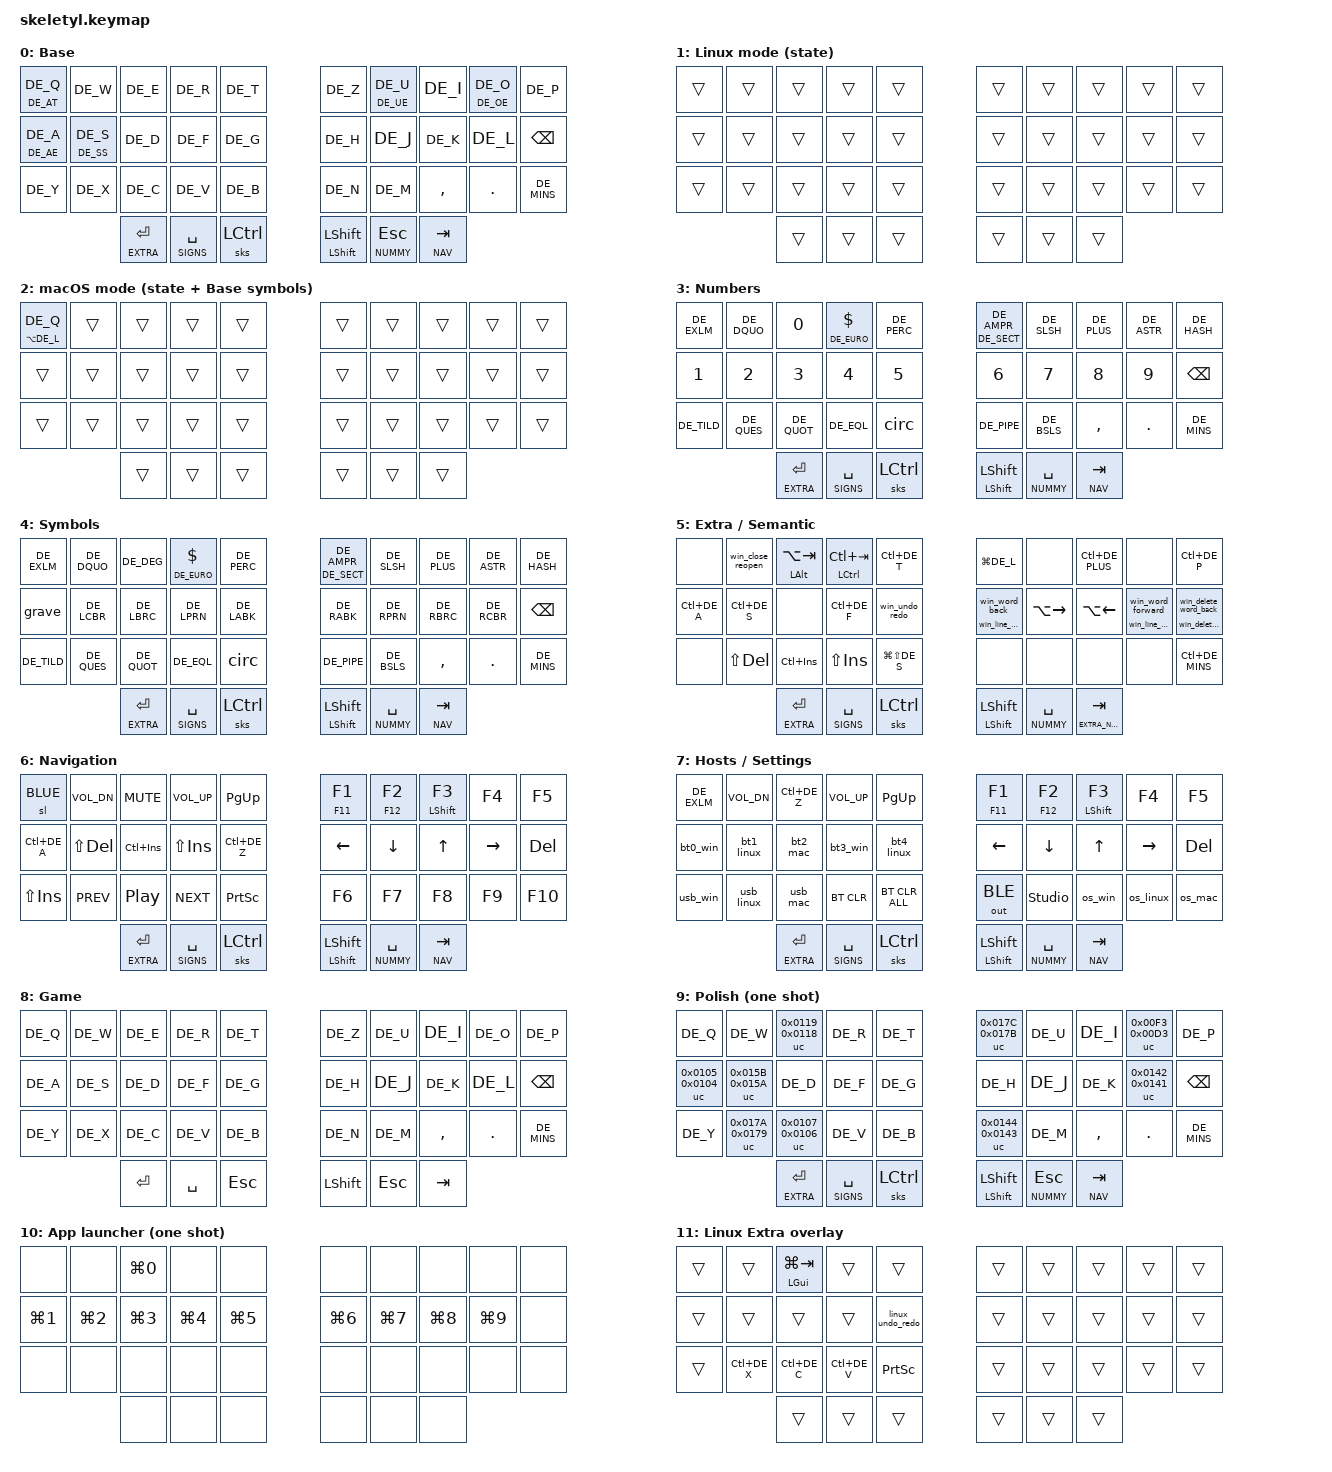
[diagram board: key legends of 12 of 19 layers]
#include "german-keymap.h"
#include <behaviors.dtsi>
#include <behaviors/unicode.dtsi>
#include <dt-bindings/zmk/keys.h>
#include <dt-bindings/zmk/bt.h>
#include <dt-bindings/zmk/outputs.h>
#include <dt-bindings/zmk/modifiers.h>

// Hardware-specific settings action. Boards with RGB can override this before
// including this keymap; the Skeletyl keeps its existing BLUE+Q exclamation.
#ifndef SETTINGS_PRIMARY
#define SETTINGS_PRIMARY &kp DE_EXLM
#endif

#define DEFAULT       0
// OS state layers deliberately sit below every functional layer. This lets
// macOS override Base symbols without leaking those overrides into NUMMY, etc.
#define LINUX_MODE    1
#define MAC_MODE      2
#define NUMMY         3
#define SIGNS         4
#define EXTRA         5
#define NAV           6
#define BLUE          7
#define GAME          8
#define POLISH        9
#define APP          10
#define LINUX_EXTRA  11
#define LINUX_NAV    12
#define MAC_EXTRA    13
#define MAC_NAV      14
#define MAC_NUMMY    15
#define MAC_SIGNS    16
#define EXTRA_NUM    17
#define MAC_EXTRA_NUM 18

#define STICKY_TIMEOUT_MS 500

&mt {
    flavor = "tap-preferred";
    tapping-term-ms = <180>;
};

&lt {
    tapping-term-ms = <160>;
};


// Unicode input. OS selectors below keep this mode in sync with the host.
&uc {
    default-mode = <UC_MODE_LINUX>;
};

/ {
    behaviors {
        sks: sticky_modifier {
            compatible = "zmk,behavior-sticky-key";
            #binding-cells = <1>;
            display-name = "Sticky modifier (500 ms)";
            bindings = <&kp>;
            release-after-ms = <STICKY_TIMEOUT_MS>;
            // Deliberately no quick-release: this keeps the sticky modifier active
            // through the full next key press/release and avoids known interactions
            // with hold-tap based switcher keys.
            ignore-modifiers;
        };


        // Polish one-shot layer that survives modifier presses. Unlike ZMK's
        // standard &sl (quick-release), this stays active through Shift and
        // releases only after the actual non-modifier Polish key is released.
        pls: polish_sticky_layer {
            compatible = "zmk,behavior-sticky-key";
            #binding-cells = <1>;
            display-name = "Polish one-shot (modifier aware)";
            bindings = <&mo>;
            release-after-ms = <2000>;
            ignore-modifiers;
        };

        // Unicode needs Shift to remain active while &uc evaluates the key.
        // No quick-release here: tap Shift, then the Polish letter.
        pl_sks: polish_sticky_shift {
            compatible = "zmk,behavior-sticky-key";
            #binding-cells = <1>;
            display-name = "Polish sticky Shift";
            bindings = <&kp>;
            release-after-ms = <1500>;
            ignore-modifiers;
        };

        // Right Shift thumb: quick tap keeps the existing sticky-Shift UX;
        // holding it behaves like a normal physical Shift. This is essential
        // for repeatedly walking backwards through an open switcher.
        shft: shift_hold_sticky_tap {
            compatible = "zmk,behavior-hold-tap";
            #binding-cells = <2>;
            display-name = "Shift hold / sticky tap";
            flavor = "hold-preferred";
            tapping-term-ms = <180>;
            quick-tap-ms = <0>;
            bindings = <&kp>, <&sks>;
        };

        // Same dual Shift on the Polish layer, but the tap uses the
        // non-quick-release sticky Shift so Unicode reliably sees Shift.
        pl_shft: polish_shift_hold_sticky_tap {
            compatible = "zmk,behavior-hold-tap";
            #binding-cells = <2>;
            display-name = "Polish Shift hold / sticky tap";
            flavor = "hold-preferred";
            tapping-term-ms = <180>;
            quick-tap-ms = <0>;
            bindings = <&kp>, <&pl_sks>;
        };

        tog_on: toggle_layer_on_only {
            compatible = "zmk,behavior-toggle-layer";
            #binding-cells = <1>;
            display-name = "Layer ON";
            toggle-mode = "on";
        };

        tog_off: toggle_layer_off_only {
            compatible = "zmk,behavior-toggle-layer";
            #binding-cells = <1>;
            display-name = "Layer OFF";
            toggle-mode = "off";
        };

        hm: function_shift {
            compatible = "zmk,behavior-hold-tap";
            #binding-cells = <2>;
            display-name = "Function / Shift";
            tapping-term-ms = <150>;
            quick-tap-ms = <0>;
            flavor = "tap-preferred";
            bindings = <&kp>, <&kp>;
        };

        pht: positional_hold_tap {
            compatible = "zmk,behavior-hold-tap";
            #binding-cells = <2>;
            display-name = "Positional hold-tap";
            flavor = "hold-preferred";
            tapping-term-ms = <180>;
            quick-tap-ms = <180>;
            bindings = <&kp>, <&kp>;
            hold-trigger-key-positions = <29>;
        };

        // Robust switcher key: tap sends a complete one-step shortcut; hold sends
        // only the underlying modifier. There are no macros, toggles, or cross-key
        // cleanup states, so releasing the physical E/R key always releases the
        // modifier via normal &kp semantics.
        //
        // Usage examples:
        //   &swh LALT  LA(TAB)  -> tap: Alt+Tab, hold: Alt (Windows)
        //   &swh LGUI  LG(TAB)  -> tap: Super/Cmd+Tab, hold: Super/Cmd (Linux/macOS)
        //   &swh LCTRL LC(TAB)  -> tap: Ctrl+Tab, hold: Ctrl
        swh: switcher_hold_tap {
            compatible = "zmk,behavior-hold-tap";
            #binding-cells = <2>;
            display-name = "Switcher tap / hold modifier";
            flavor = "hold-preferred";
            tapping-term-ms = <180>;
            quick-tap-ms = <0>;
            // The hold modifier is asserted immediately. Because the tap action
            // contains that same modifier (Alt/Super/Ctrl + Tab), linger keeps the
            // modifier continuous across the tap decision instead of releasing and
            // pressing it again.
            hold-while-undecided;
            hold-while-undecided-linger;
            bindings = <&kp>, <&kp>;
        };

        // EXTRA right outer thumb: tapping remains Tab for app/tab switchers,
        // while pressing immediately exposes the forward-delete overlay so a
        // following Backspace is handled as Delete. Holding selects the layer.
        fwd: forward_delete_tab {
            compatible = "zmk,behavior-hold-tap";
            #binding-cells = <2>;
            display-name = "Forward delete layer / Tab";
            flavor = "tap-preferred";
            tapping-term-ms = <180>;
            quick-tap-ms = <0>;
            hold-while-undecided;
            bindings = <&mo>, <&kp>;
        };


        // Semantic shortcuts with Shift-aware alternate actions. App/tab switching uses
        // only the hold-tap above and normal &kp events; there is no latched modifier
        // state to clean up.
        win_close_reopen: win_close_reopen {
            compatible = "zmk,behavior-mod-morph";
            #binding-cells = <0>;
            display-name = "Close / Reopen tab";
            bindings = <&kp LC(DE_W)>, <&kp LC(LS(DE_T))>;
            mods = <(MOD_LSFT|MOD_RSFT)>;
        };

        mac_close_reopen: mac_close_reopen {
            compatible = "zmk,behavior-mod-morph";
            #binding-cells = <0>;
            display-name = "Close / Reopen tab (macOS)";
            bindings = <&kp LG(DE_W)>, <&kp LG(LS(DE_T))>;
            mods = <(MOD_LSFT|MOD_RSFT)>;
        };


        win_undo_redo: win_undo_redo {
            compatible = "zmk,behavior-mod-morph";
            #binding-cells = <0>;
            display-name = "Undo / Redo (Windows)";
            bindings = <&kp LC(DE_Z)>, <&kp LC(DE_Y)>;
            mods = <(MOD_LSFT|MOD_RSFT)>;
        };

        linux_undo_redo: linux_undo_redo {
            compatible = "zmk,behavior-mod-morph";
            #binding-cells = <0>;
            display-name = "Undo / Redo (Linux)";
            bindings = <&kp LC(DE_Z)>, <&kp LC(LS(DE_Z))>;
            mods = <(MOD_LSFT|MOD_RSFT)>;
        };

        mac_undo_redo: mac_undo_redo {
            compatible = "zmk,behavior-mod-morph";
            #binding-cells = <0>;
            display-name = "Undo / Redo (macOS)";
            bindings = <&kp LG(DE_Z)>, <&kp LG(LS(DE_Z))>;
            mods = <(MOD_LSFT|MOD_RSFT)>;
        };

        // EXTRA is semantic: the same physical key performs the same editing
        // operation on every OS. Shift extends the operation to selection or
        // deletion up to the corresponding line boundary.
        win_word_back: win_word_back {
            compatible = "zmk,behavior-mod-morph";
            #binding-cells = <0>;
            display-name = "Word back / select word back";
            bindings = <&kp LC(LEFT)>, <&kp LC(LS(LEFT))>;
            mods = <(MOD_LSFT|MOD_RSFT)>;
        };

        win_word_forward: win_word_forward {
            compatible = "zmk,behavior-mod-morph";
            #binding-cells = <0>;
            display-name = "Word forward / select word forward";
            bindings = <&kp LC(RIGHT)>, <&kp LC(LS(RIGHT))>;
            mods = <(MOD_LSFT|MOD_RSFT)>;
        };

        win_line_start: win_line_start {
            compatible = "zmk,behavior-mod-morph";
            #binding-cells = <0>;
            display-name = "Line start / select to line start";
            bindings = <&kp HOME>, <&kp LS(HOME)>;
            mods = <(MOD_LSFT|MOD_RSFT)>;
        };

        win_line_end: win_line_end {
            compatible = "zmk,behavior-mod-morph";
            #binding-cells = <0>;
            display-name = "Line end / select to line end";
            bindings = <&kp END>, <&kp LS(END)>;
            mods = <(MOD_LSFT|MOD_RSFT)>;
        };

        mac_word_back: mac_word_back {
            compatible = "zmk,behavior-mod-morph";
            #binding-cells = <0>;
            display-name = "Word back / select word back (macOS)";
            bindings = <&kp LA(LEFT)>, <&kp LA(LS(LEFT))>;
            mods = <(MOD_LSFT|MOD_RSFT)>;
        };

        mac_word_forward: mac_word_forward {
            compatible = "zmk,behavior-mod-morph";
            #binding-cells = <0>;
            display-name = "Word forward / select word forward (macOS)";
            bindings = <&kp LA(RIGHT)>, <&kp LA(LS(RIGHT))>;
            mods = <(MOD_LSFT|MOD_RSFT)>;
        };

        mac_line_start: mac_line_start {
            compatible = "zmk,behavior-mod-morph";
            #binding-cells = <0>;
            display-name = "Line start / select to line start (macOS)";
            bindings = <&kp LG(LEFT)>, <&kp LG(LS(LEFT))>;
            mods = <(MOD_LSFT|MOD_RSFT)>;
        };

        mac_line_end: mac_line_end {
            compatible = "zmk,behavior-mod-morph";
            #binding-cells = <0>;
            display-name = "Line end / select to line end (macOS)";
            bindings = <&kp LG(RIGHT)>, <&kp LG(LS(RIGHT))>;
            mods = <(MOD_LSFT|MOD_RSFT)>;
        };

        // Short H/L moves by word; holding the same key moves to the matching
        // line boundary. The nested mod-morphs above preserve Shift selection.
        // ZMK hold-taps always expose two binding cells; these fixed-action
        // instances are therefore invoked with two ignored zero parameters.
        win_semantic_h: win_semantic_h {
            compatible = "zmk,behavior-hold-tap";
            #binding-cells = <2>;
            display-name = "Word back / line start";
            flavor = "tap-preferred";
            tapping-term-ms = <180>;
            quick-tap-ms = <0>;
            bindings = <&win_line_start>, <&win_word_back>;
        };

        win_semantic_l: win_semantic_l {
            compatible = "zmk,behavior-hold-tap";
            #binding-cells = <2>;
            display-name = "Word forward / line end";
            flavor = "tap-preferred";
            tapping-term-ms = <180>;
            quick-tap-ms = <0>;
            bindings = <&win_line_end>, <&win_word_forward>;
        };

        mac_semantic_h: mac_semantic_h {
            compatible = "zmk,behavior-hold-tap";
            #binding-cells = <2>;
            display-name = "Word back / line start (macOS)";
            flavor = "tap-preferred";
            tapping-term-ms = <180>;
            quick-tap-ms = <0>;
            bindings = <&mac_line_start>, <&mac_word_back>;
        };

        mac_semantic_l: mac_semantic_l {
            compatible = "zmk,behavior-hold-tap";
            #binding-cells = <2>;
            display-name = "Word forward / line end (macOS)";
            flavor = "tap-preferred";
            tapping-term-ms = <180>;
            quick-tap-ms = <0>;
            bindings = <&mac_line_end>, <&mac_word_forward>;
        };

        win_delete_back: win_delete_back {
            compatible = "zmk,behavior-hold-tap";
            #binding-cells = <2>;
            display-name = "Delete word back / delete to line start";
            flavor = "tap-preferred";
            tapping-term-ms = <250>;
            quick-tap-ms = <0>;
            bindings = <&win_delete_line_back>, <&win_delete_word_back>;
        };

        win_delete_forward: win_delete_forward {
            compatible = "zmk,behavior-hold-tap";
            #binding-cells = <2>;
            display-name = "Delete word forward / delete to line end";
            flavor = "tap-preferred";
            tapping-term-ms = <250>;
            quick-tap-ms = <0>;
            bindings = <&win_delete_line_forward>, <&win_delete_word_forward>;
        };

        mac_delete_back: mac_delete_back {
            compatible = "zmk,behavior-hold-tap";
            #binding-cells = <2>;
            display-name = "Delete word back / delete to line start (macOS)";
            flavor = "tap-preferred";
            tapping-term-ms = <250>;
            quick-tap-ms = <0>;
            bindings = <&mac_delete_line_back>, <&mac_delete_word_back>;
        };

        mac_delete_forward: mac_delete_forward {
            compatible = "zmk,behavior-hold-tap";
            #binding-cells = <2>;
            display-name = "Delete word forward / delete to line end (macOS)";
            flavor = "tap-preferred";
            tapping-term-ms = <250>;
            quick-tap-ms = <0>;
            bindings = <&mac_delete_line_forward>, <&mac_delete_word_forward>;
        };
    };

    macros {

        grave: grave {
            compatible = "zmk,behavior-macro";
            #binding-cells = <0>;
            display-name = "Grave";
            wait-ms = <10>;
            tap-ms = <10>;
            bindings = <&kp DE_GRV>, <&kp SPACE>;
        };

        circ: circ {
            compatible = "zmk,behavior-macro";
            #binding-cells = <0>;
            display-name = "Circumflex";
            wait-ms = <10>;
            tap-ms = <10>;
            bindings = <&kp DE_CIRC>, <&kp SPACE>;
        };

        mac_tilde: mac_tilde {
            compatible = "zmk,behavior-macro";
            #binding-cells = <0>;
            display-name = "Tilde (macOS German)";
            wait-ms = <10>;
            tap-ms = <10>;
            bindings = <&kp LA(DE_N)>, <&kp SPACE>;
        };

        win_delete_word_back: win_delete_word_back {
            compatible = "zmk,behavior-macro";
            #binding-cells = <0>;
            display-name = "Delete previous word";
            wait-ms = <0>;
            tap-ms = <10>;
            bindings = <&kp LC(BSPC)>;
        };

        win_delete_word_forward: win_delete_word_forward {
            compatible = "zmk,behavior-macro";
            #binding-cells = <0>;
            display-name = "Delete next word";
            wait-ms = <0>;
            tap-ms = <10>;
            bindings = <&kp LC(DEL)>;
        };

        mac_delete_word_back: mac_delete_word_back {
            compatible = "zmk,behavior-macro";
            #binding-cells = <0>;
            display-name = "Delete previous word (macOS)";
            wait-ms = <0>;
            tap-ms = <10>;
            bindings = <&kp LA(BSPC)>;
        };

        mac_delete_word_forward: mac_delete_word_forward {
            compatible = "zmk,behavior-macro";
            #binding-cells = <0>;
            display-name = "Delete next word (macOS)";
            wait-ms = <0>;
            tap-ms = <10>;
            bindings = <&kp LA(DEL)>;
        };

        win_delete_line_back: win_delete_line_back {
            compatible = "zmk,behavior-macro";
            #binding-cells = <0>;
            display-name = "Delete to line start";
            wait-ms = <10>;
            tap-ms = <10>;
            bindings = <&kp LS(HOME)>, <&kp BSPC>;
        };

        win_delete_line_forward: win_delete_line_forward {
            compatible = "zmk,behavior-macro";
            #binding-cells = <0>;
            display-name = "Delete to line end";
            wait-ms = <10>;
            tap-ms = <10>;
            bindings = <&kp LS(END)>, <&kp DEL>;
        };

        mac_delete_line_back: mac_delete_line_back {
            compatible = "zmk,behavior-macro";
            #binding-cells = <0>;
            display-name = "Delete to line start (macOS)";
            wait-ms = <10>;
            tap-ms = <10>;
            bindings = <&kp LG(LS(LEFT))>, <&kp BSPC>;
        };

        mac_delete_line_forward: mac_delete_line_forward {
            compatible = "zmk,behavior-macro";
            #binding-cells = <0>;
            display-name = "Delete to line end (macOS)";
            wait-ms = <10>;
            tap-ms = <10>;
            bindings = <&kp LG(LS(RIGHT))>, <&kp DEL>;
        };

        // Bluetooth host selectors. Each selector sets profile, output, shortcut OS state,
        // and the matching Unicode input method. Edit the profile/OS association to match your hosts.
        bt0_win: bt0_win {
            compatible = "zmk,behavior-macro";
            #binding-cells = <0>;
            display-name = "BT 0 - Windows";
            wait-ms = <50>;
            tap-ms = <10>;
            bindings = <&bt BT_SEL 0>, <&out OUT_BLE>, <&os_win>;
        };

        bt1_linux: bt1_linux {
            compatible = "zmk,behavior-macro";
            #binding-cells = <0>;
            display-name = "BT 1 - Linux";
            wait-ms = <50>;
            tap-ms = <10>;
            bindings = <&bt BT_SEL 1>, <&out OUT_BLE>, <&os_linux>;
        };

        bt2_mac: bt2_mac {
            compatible = "zmk,behavior-macro";
            #binding-cells = <0>;
            display-name = "BT 2 - macOS";
            wait-ms = <50>;
            tap-ms = <10>;
            bindings = <&bt BT_SEL 2>, <&out OUT_BLE>, <&os_mac>;
        };

        bt3_win: bt3_win {
            compatible = "zmk,behavior-macro";
            #binding-cells = <0>;
            display-name = "BT 3 - Windows";
            wait-ms = <50>;
            tap-ms = <10>;
            bindings = <&bt BT_SEL 3>, <&out OUT_BLE>, <&os_win>;
        };

        bt4_linux: bt4_linux {
            compatible = "zmk,behavior-macro";
            #binding-cells = <0>;
            display-name = "BT 4 - Linux";
            wait-ms = <50>;
            tap-ms = <10>;
            bindings = <&bt BT_SEL 4>, <&out OUT_BLE>, <&os_linux>;
        };

        os_win: os_win {
            compatible = "zmk,behavior-macro";
            #binding-cells = <0>;
            display-name = "Windows mode";
            wait-ms = <0>;
            tap-ms = <0>;
            bindings = <&tog_off LINUX_MODE>, <&tog_off MAC_MODE>, <&uc UC_SET_WIN_COMPOSE>;
        };

        os_linux: os_linux {
            compatible = "zmk,behavior-macro";
            #binding-cells = <0>;
            display-name = "Linux mode";
            wait-ms = <0>;
            tap-ms = <0>;
            bindings = <&tog_on LINUX_MODE>, <&tog_off MAC_MODE>, <&uc UC_SET_LINUX>;
        };

        usb_win: usb_win {
            compatible = "zmk,behavior-macro";
            #binding-cells = <0>;
            display-name = "USB - Windows";
            wait-ms = <30>;
            tap-ms = <10>;
            bindings = <&out OUT_USB>, <&os_win>;
        };

        usb_linux: usb_linux {
            compatible = "zmk,behavior-macro";
            #binding-cells = <0>;
            display-name = "USB - Linux";
            wait-ms = <30>;
            tap-ms = <10>;
            bindings = <&out OUT_USB>, <&os_linux>;
        };

        usb_mac: usb_mac {
            compatible = "zmk,behavior-macro";
            #binding-cells = <0>;
            display-name = "USB - macOS";
            wait-ms = <30>;
            tap-ms = <10>;
            bindings = <&out OUT_USB>, <&os_mac>;
        };

        os_mac: os_mac {
            compatible = "zmk,behavior-macro";
            #binding-cells = <0>;
            display-name = "macOS mode";
            wait-ms = <0>;
            tap-ms = <0>;
            bindings = <&tog_off LINUX_MODE>, <&tog_on MAC_MODE>, <&uc UC_SET_MACOS>;
        };
    };

    combos {
        compatible = "zmk,combos";

        combo_app_launcher {
            timeout-ms = <80>;
            key-positions = <16 17 34>;
            layers = <DEFAULT NUMMY SIGNS EXTRA NAV BLUE POLISH LINUX_MODE MAC_MODE LINUX_EXTRA LINUX_NAV MAC_EXTRA MAC_NAV MAC_NUMMY MAC_SIGNS EXTRA_NUM MAC_EXTRA_NUM>;
            bindings = <&sl APP>;
        };

        combo_esc {
            timeout-ms = <80>;
            key-positions = <11 12 13 31>;
            layers = <DEFAULT NUMMY SIGNS EXTRA NAV BLUE POLISH LINUX_MODE MAC_MODE LINUX_EXTRA LINUX_NAV MAC_EXTRA MAC_NAV MAC_NUMMY MAC_SIGNS EXTRA_NUM MAC_EXTRA_NUM>;
            bindings = <&kp ESC>;
        };

        combo_del {
            timeout-ms = <80>;
            key-positions = <1 2 3>;
            layers = <DEFAULT NUMMY SIGNS EXTRA NAV BLUE POLISH LINUX_MODE MAC_MODE LINUX_EXTRA LINUX_NAV MAC_EXTRA MAC_NAV MAC_NUMMY MAC_SIGNS EXTRA_NUM MAC_EXTRA_NUM>;
            bindings = <&kp DEL>;
        };

        combo_bspc {
            timeout-ms = <80>;
            key-positions = <21 22 23>;
            layers = <DEFAULT NUMMY SIGNS EXTRA NAV BLUE POLISH LINUX_MODE MAC_MODE LINUX_EXTRA LINUX_NAV MAC_EXTRA MAC_NAV MAC_NUMMY MAC_SIGNS EXTRA_NUM MAC_EXTRA_NUM>;
            bindings = <&kp BSPC>;
        };

        fishy {
            timeout-ms = <80>;
            key-positions = <17 18 34>;
            layers = <DEFAULT NUMMY SIGNS EXTRA NAV BLUE POLISH LINUX_MODE MAC_MODE LINUX_EXTRA LINUX_NAV MAC_EXTRA MAC_NAV MAC_NUMMY MAC_SIGNS EXTRA_NUM MAC_EXTRA_NUM>;
            bindings = <&kp LA(M)>;
        };

        // Left-hand-only modifier combos.
        // Left outer + left middle thumbs (30 + 31) -> sticky Alt / Option.
        // This fully overlaps the 30+31+32 game combo; ZMK supports fully
        // overlapping combos, and both use the same timeout.
        combo_alt {
            timeout-ms = <80>;
            key-positions = <30 31>;
            layers = <DEFAULT NUMMY SIGNS EXTRA NAV BLUE POLISH LINUX_MODE MAC_MODE LINUX_EXTRA LINUX_NAV MAC_EXTRA MAC_NAV MAC_NUMMY MAC_SIGNS EXTRA_NUM MAC_EXTRA_NUM>;
            bindings = <&sks LALT>;
        };

        // Left-hand GUI / Win / Command combo. Sticky again by request so it can
        // be composed sequentially, e.g. tap GUI combo, then tap Space for Cmd+Space.
        combo_lgui {
            timeout-ms = <80>;
            key-positions = <12 13 31>;
            layers = <DEFAULT NUMMY SIGNS EXTRA NAV BLUE POLISH LINUX_MODE MAC_MODE LINUX_EXTRA LINUX_NAV MAC_EXTRA MAC_NAV MAC_NUMMY MAC_SIGNS EXTRA_NUM MAC_EXTRA_NUM>;
            bindings = <&sks LGUI>;
        };

        // Left middle + left inner thumbs (31 + 32) -> sticky Shift.
        // This keeps Shift fully on the left thumb cluster, next to Ctrl/Alt.
        combo_shift {
            timeout-ms = <80>;
            key-positions = <31 32>;
            layers = <DEFAULT NUMMY SIGNS EXTRA NAV BLUE POLISH LINUX_MODE MAC_MODE LINUX_EXTRA LINUX_NAV MAC_EXTRA MAC_NAV MAC_NUMMY MAC_SIGNS EXTRA_NUM MAC_EXTRA_NUM>;
            bindings = <&sks LSHFT>;
        };

        tmux {
            timeout-ms = <80>;
            key-positions = <11 12 31>;
            layers = <DEFAULT NUMMY SIGNS EXTRA NAV BLUE POLISH LINUX_MODE MAC_MODE LINUX_EXTRA LINUX_NAV MAC_EXTRA MAC_NAV MAC_NUMMY MAC_SIGNS EXTRA_NUM MAC_EXTRA_NUM>;
            bindings = <&kp LA(J)>;
        };

        // Right middle + right outer thumbs (34 + 35) -> Polish for one key.
        // This avoids the old three-thumb gesture and keeps Polish off EXTRA.
        combo_polish {
            timeout-ms = <80>;
            key-positions = <34 35>;
            layers = <DEFAULT NUMMY SIGNS EXTRA NAV BLUE LINUX_MODE MAC_MODE LINUX_EXTRA LINUX_NAV MAC_EXTRA MAC_NAV MAC_NUMMY MAC_SIGNS EXTRA_NUM MAC_EXTRA_NUM>;
            bindings = <&pls POLISH>;
        };

        game_on {
            timeout-ms = <80>;
            key-positions = <30 31 32>;
            layers = <DEFAULT LINUX_MODE MAC_MODE>;
            bindings = <&tog_on GAME>;
        };

        game_off {
            timeout-ms = <80>;
            key-positions = <30 31 32>;
            layers = <GAME>;
            bindings = <&tog_off GAME>;
        };

    };

    conditional_layers {
        compatible = "zmk,conditional-layers";

        linux_extra {
            if-layers = <LINUX_MODE EXTRA>;
            then-layer = <LINUX_EXTRA>;
        };

        linux_nav {
            if-layers = <LINUX_MODE NAV>;
            then-layer = <LINUX_NAV>;
        };

        mac_extra {
            if-layers = <MAC_MODE EXTRA>;
            then-layer = <MAC_EXTRA>;
        };

        mac_nav {
            if-layers = <MAC_MODE NAV>;
            then-layer = <MAC_NAV>;
        };

        mac_nummy {
            if-layers = <MAC_MODE NUMMY>;
            then-layer = <MAC_NUMMY>;
        };

        mac_signs {
            if-layers = <MAC_MODE SIGNS>;
            then-layer = <MAC_SIGNS>;
        };

        mac_extra_num {
            if-layers = <MAC_MODE EXTRA_NUM>;
            then-layer = <MAC_EXTRA_NUM>;
        };
    };

    keymap {
        compatible = "zmk,keymap";

        default_layer {
            display-name = "Base";
            bindings = <
&pht DE_AT DE_Q  &kp DE_W  &kp DE_E  &kp DE_R  &kp DE_T             &kp DE_Z  &pht DE_UE DE_U  &kp DE_I  &pht DE_OE DE_O  &kp DE_P
&pht DE_AE DE_A  &pht DE_SS DE_S  &kp DE_D  &kp DE_F  &kp DE_G     &kp DE_H  &kp DE_J  &kp DE_K  &kp DE_L  &kp BSPC
&kp DE_Y  &kp DE_X  &kp DE_C  &kp DE_V  &kp DE_B                    &kp DE_N  &kp DE_M  &kp COMMA  &kp DOT  &kp DE_MINS
                 &lt EXTRA RET  &lt SIGNS SPACE  &sks LCTRL          &shft LSHFT LSHFT  &lt NUMMY ESC  &lt NAV TAB
            >;
        };

        linux_mode_layer {
            display-name = "Linux mode (state)";
            bindings = <
&trans &trans &trans &trans &trans   &trans &trans &trans &trans &trans
&trans &trans &trans &trans &trans   &trans &trans &trans &trans &trans
&trans &trans &trans &trans &trans   &trans &trans &trans &trans &trans
             &trans &trans &trans   &trans &trans &trans
            >;
        };

        mac_mode_layer {
            display-name = "macOS mode (state + Base symbols)";
            // On German macOS, @ is Option+L rather than AltGr+Q. This low
            // priority state layer only overrides the Base Q/@ hold-tap.
            bindings = <
&pht LA(DE_L) DE_Q  &trans &trans &trans &trans   &trans &trans &trans &trans &trans
&trans &trans &trans &trans &trans                &trans &trans &trans &trans &trans
&trans &trans &trans &trans &trans                &trans &trans &trans &trans &trans
                  &trans &trans &trans            &trans &trans &trans
            >;
        };

        nummy_layer {
            display-name = "Numbers";
            bindings = <
&kp DE_EXLM  &kp DE_DQUO  &kp N0  &mt DE_EURO DLLR  &kp DE_PERC    &mt DE_SECT DE_AMPR  &kp DE_SLSH  &kp DE_PLUS  &kp DE_ASTR  &kp DE_HASH
&kp N1  &kp N2  &kp N3  &kp N4  &kp N5                               &kp N6  &kp N7  &kp N8  &kp N9  &kp BSPC
&kp DE_TILD  &kp DE_QUES  &kp DE_QUOT  &kp DE_EQL  &circ            &kp DE_PIPE  &kp DE_BSLS  &kp COMMA  &kp DOT  &kp DE_MINS
                 &lt EXTRA RET  &lt SIGNS SPACE  &sks LCTRL          &shft LSHFT LSHFT  &lt NUMMY SPACE  &lt NAV TAB
            >;
        };

        signs_layer {
            display-name = "Symbols";
            bindings = <
&kp DE_EXLM  &kp DE_DQUO  &kp DE_DEG  &mt DE_EURO DLLR  &kp DE_PERC  &mt DE_SECT DE_AMPR  &kp DE_SLSH  &kp DE_PLUS  &kp DE_ASTR  &kp DE_HASH
&grave  &kp DE_LCBR  &kp DE_LBRC  &kp DE_LPRN  &kp DE_LABK           &kp DE_RABK  &kp DE_RPRN  &kp DE_RBRC  &kp DE_RCBR  &kp BSPC
&kp DE_TILD  &kp DE_QUES  &kp DE_QUOT  &kp DE_EQL  &circ             &kp DE_PIPE  &kp DE_BSLS  &kp COMMA  &kp DOT  &kp DE_MINS
                 &lt EXTRA RET  &lt SIGNS SPACE  &sks LCTRL           &shft LSHFT LSHFT  &lt NUMMY SPACE  &lt NAV TAB
            >;
        };

        extra_layer {
            display-name = "Extra / Semantic";
            // Clean semantic command layer: no media controls, no Polish hold-taps,
            // and no duplicate HJKL navigation. Unused positions intentionally swallow input.
            // W = close tab; Shift+W = reopen closed tab
            // E tap = one app switch immediately; E hold = hold the OS app-switch modifier.
            // On EXTRA the right outer NAV thumb is Tab when tapped and immediately
            // exposes the forward-delete overlay while pressed. It therefore still
            // cycles while E/R is held; Shift+Tab reverses.
            // R tap = one Ctrl+Tab immediately; R hold = hold Ctrl; the same Tab thumb cycles.
            // T = new tab; A = select all; S = save; F = find
            // G = undo; Shift+G = redo; Windows uses X=Shift+Del, C=Ctrl+Ins, V=Shift+Ins.
            // Tap H/L = word back/forward; hold H/L = line start/end; Shift selects.
            // K/J = history back/forward, matching terminal/Vim history direction.
            // Tap Backspace = delete previous word; hold = delete to line start.
            // Hold NAV + tap/hold Backspace = delete next word/to line end. Z = lock.
            bindings = <
&none  &win_close_reopen  &swh LALT LA(TAB)  &swh LCTRL LC(TAB)  &kp LC(DE_T)        &kp LG(DE_L)  &none  &kp LC(DE_PLUS)  &none  &kp LC(DE_P)
&kp LC(DE_A)  &kp LC(DE_S)  &none  &kp LC(DE_F)  &win_undo_redo        &win_semantic_h 0 0  &kp LA(RIGHT)  &kp LA(LEFT)  &win_semantic_l 0 0  &win_delete_back 0 0
&none  &kp LS(DEL)  &kp LC(INS)  &kp LS(INS)  &kp LG(LS(DE_S))      &none  &none  &none  &none  &kp LC(DE_MINS)
                 &lt EXTRA RET  &lt SIGNS SPACE  &sks LCTRL              &shft LSHFT LSHFT  &lt NUMMY SPACE  &fwd EXTRA_NUM TAB
            >;
        };

        nav_layer {
            display-name = "Navigation";
            bindings = <
&sl BLUE  &kp C_VOL_DN  &kp C_MUTE  &kp C_VOL_UP  &kp PG_UP          &mt F11 F1  &mt F12 F2  &hm LSHFT F3  &kp F4  &kp F5
&kp LC(DE_A)  &kp LS(DEL)  &kp LC(INS)  &kp LS(INS)  &kp LC(DE_Z)  &kp LEFT  &kp DOWN  &kp UP  &kp RIGHT  &kp DEL
&kp LS(INS)  &kp C_PREV  &kp C_PP  &kp C_NEXT  &kp PSCRN             &kp F6  &kp F7  &kp F8  &kp F9  &kp F10
                 &lt EXTRA RET  &lt SIGNS SPACE  &sks LCTRL           &shft LSHFT LSHFT  &lt NUMMY SPACE  &lt NAV TAB
            >;
        };

        blue_layer {
            display-name = "Hosts / Settings";
            // Host layout mnemonic:
            //   row 2, A/S/D = Bluetooth Windows/Linux/macOS
            //   row 3, Y/X/C = USB       Windows/Linux/macOS
            // Additional BT profiles remain on F/G; recovery/settings occupy the rest.
            bindings = <
SETTINGS_PRIMARY  &kp C_VOL_DN  &kp LC(DE_Z)  &kp C_VOL_UP  &kp PG_UP     &mt F11 F1  &mt F12 F2  &hm LSHFT F3  &kp F4  &kp F5
&bt0_win  &bt1_linux  &bt2_mac  &bt3_win  &bt4_linux                 &kp LEFT  &kp DOWN  &kp UP  &kp RIGHT  &kp DEL
&usb_win  &usb_linux  &usb_mac  &bt BT_CLR  &bt BT_CLR_ALL           &out OUT_BLE  &studio_unlock  &os_win  &os_linux  &os_mac
                 &lt EXTRA RET  &lt SIGNS SPACE  &sks LCTRL           &shft LSHFT LSHFT  &lt NUMMY SPACE  &lt NAV TAB
            >;
        };

        game_layer {
            display-name = "Game";
            bindings = <
&kp DE_Q  &kp DE_W  &kp DE_E  &kp DE_R  &kp DE_T                     &kp DE_Z  &kp DE_U  &kp DE_I  &kp DE_O  &kp DE_P
&kp DE_A  &kp DE_S  &kp DE_D  &kp DE_F  &kp DE_G                     &kp DE_H  &kp DE_J  &kp DE_K  &kp DE_L  &kp BSPC
&kp DE_Y  &kp DE_X  &kp DE_C  &kp DE_V  &kp DE_B                     &kp DE_N  &kp DE_M  &kp COMMA  &kp DOT  &kp DE_MINS
                 &kp ENTER  &kp SPACE  &kp ESC                       &kp LSHFT  &kp ESC  &kp TAB
            >;
        };

        polish_layer {
            display-name = "Polish (one shot)";
            bindings = <
&kp DE_Q  &kp DE_W  &uc 0x0119 0x0118  &kp DE_R  &kp DE_T       &uc 0x017C 0x017B  &kp DE_U  &kp DE_I  &uc 0x00F3 0x00D3  &kp DE_P
&uc 0x0105 0x0104  &uc 0x015B 0x015A  &kp DE_D  &kp DE_F  &kp DE_G       &kp DE_H  &kp DE_J  &kp DE_K  &uc 0x0142 0x0141  &kp BSPC
&kp DE_Y  &uc 0x017A 0x0179  &uc 0x0107 0x0106  &kp DE_V  &kp DE_B       &uc 0x0144 0x0143  &kp DE_M  &kp COMMA  &kp DOT  &kp DE_MINS
                 &lt EXTRA RET  &lt SIGNS SPACE  &sks LCTRL          &pl_shft LSHFT LSHFT  &lt NUMMY ESC  &lt NAV TAB
            >;
        };

        app_layer {
            display-name = "App launcher (one shot)";
            // Same physical number positions as NUMMY, but each key directly
            // sends GUI+digit. The combo activates this layer for one key only.
            bindings = <
&none &none &kp LG(N0) &none &none   &none &none &none &none &none
&kp LG(N1) &kp LG(N2) &kp LG(N3) &kp LG(N4) &kp LG(N5)   &kp LG(N6) &kp LG(N7) &kp LG(N8) &kp LG(N9) &none
&none &none &none &none &none       &none &none &none &none &none
             &none &none &none      &none &none &none
            >;
        };

        linux_extra_layer {
            display-name = "Linux Extra overlay";
            bindings = <
&trans &trans &swh LGUI LG(TAB) &trans &trans   &trans &trans &trans &trans &trans
&trans &trans &trans &trans &linux_undo_redo  &trans &trans &trans &trans &trans
&trans &kp LC(DE_X) &kp LC(DE_C) &kp LC(DE_V) &kp PSCRN          &trans &trans &trans &trans &trans
             &trans &trans &trans              &trans &trans &trans
            >;
        };

        linux_nav_layer {
            display-name = "Linux Nav overlay";
            bindings = <
&trans &trans &trans &trans &trans   &trans &trans &trans &trans &trans
&trans &kp LC(DE_X) &kp LC(DE_C) &kp LC(DE_V) &trans   &trans &trans &trans &trans &trans
&kp LC(DE_V) &trans &trans &trans &trans   &trans &trans &trans &trans &trans
             &trans &trans &trans   &trans &trans &trans
            >;
        };

        mac_extra_layer {
            display-name = "macOS Extra semantic overlay";
            bindings = <
&trans  &mac_close_reopen  &swh LGUI LG(TAB)  &trans  &kp LG(DE_T)   &kp LC(LG(DE_Q)) &trans &kp LG(DE_PLUS) &trans &kp LG(DE_P)
&kp LG(DE_A)  &kp LG(DE_S)  &none  &kp LG(DE_F)  &mac_undo_redo  &mac_semantic_h 0 0 &kp LG(RIGHT) &kp LG(LEFT) &mac_semantic_l 0 0 &mac_delete_back 0 0
&trans  &kp LG(DE_X)  &kp LG(DE_C)  &kp LG(DE_V)  &kp LG(LS(N3))   &trans &trans &trans &trans &kp LG(DE_MINS)
             &trans &trans &trans   &trans &trans &trans
            >;
        };

        mac_nav_layer {
            display-name = "macOS Nav overlay";
            bindings = <
&trans &trans &trans &trans &trans   &trans &trans &trans &trans &trans
&kp LG(DE_A) &kp LG(DE_X) &kp LG(DE_C) &kp LG(DE_V) &kp LG(DE_Z)   &trans &trans &trans &trans &trans
&trans &trans &trans &trans &trans   &trans &trans &trans &trans &trans
             &trans &trans &trans   &trans &trans &trans
            >;
        };

        mac_nummy_layer {
            display-name = "macOS Numbers symbol overlay";
            bindings = <
&trans &trans &trans &trans &trans   &trans &trans &trans &trans &trans
&trans &trans &trans &trans &trans   &trans &trans &trans &trans &trans
&mac_tilde &trans &trans &trans &kp DE_LABK   &kp LA(N7) &kp LS(LA(N7)) &trans &trans &trans
             &trans &trans &trans   &trans &trans &trans
            >;
        };

        mac_signs_layer {
            display-name = "macOS Symbols overlay";
            // This Mac reports the ISO ^/° and </> positions swapped relative
            // to Windows/Linux: GRAVE produces < and NON_US_BACKSLASH produces ^.
            // Option+5/6/7/8/9 provides []|{}; Shift+Option+7 is backslash.
            bindings = <
&trans &trans &kp LS(DE_LABK) &trans &trans   &trans &trans &trans &trans &trans
&trans &kp LA(N8) &kp LA(N5) &trans &kp DE_CIRC   &kp LS(DE_CIRC) &trans &kp LA(N6) &kp LA(N9) &trans
&mac_tilde &trans &trans &trans &kp DE_LABK   &kp LA(N7) &kp LS(LA(N7)) &trans &trans &trans
             &trans &trans &trans   &trans &trans &trans
            >;
        };

        extra_num_layer {
            display-name = "EXTRA + NUM forward-delete overlay";
            bindings = <
&trans &trans &trans &trans &trans   &trans &trans &trans &trans &trans
&trans &trans &trans &trans &trans   &trans &trans &trans &trans &win_delete_forward 0 0
&trans &trans &trans &trans &trans   &trans &trans &trans &trans &trans
             &trans &trans &trans   &trans &trans &trans
            >;
        };

        mac_extra_num_layer {
            display-name = "macOS EXTRA + NUM forward-delete overlay";
            bindings = <
&trans &trans &trans &trans &trans   &trans &trans &trans &trans &trans
&trans &trans &trans &trans &trans   &trans &trans &trans &trans &mac_delete_forward 0 0
&trans &trans &trans &trans &trans   &trans &trans &trans &trans &trans
             &trans &trans &trans   &trans &trans &trans
            >;
        };
    };
};
